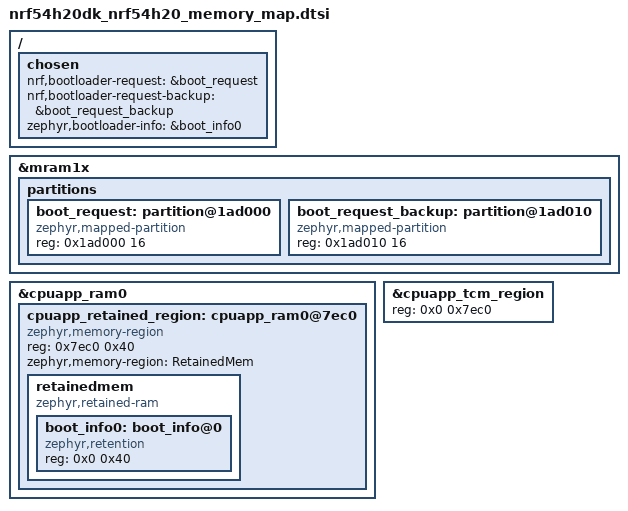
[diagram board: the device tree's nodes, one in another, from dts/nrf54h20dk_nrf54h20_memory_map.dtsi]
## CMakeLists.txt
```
#
# Copyright (c) 2025 Nordic Semiconductor ASA
#
# SPDX-License-Identifier: LicenseRef-Nordic-5-Clause
#

cmake_minimum_required(VERSION 3.20.0)

find_package(Zephyr REQUIRED HINTS $ENV{ZEPHYR_BASE})
project(ab_split)

target_sources(app PRIVATE
  src/main.c
  src/ab_utils.c
)

target_include_directories(app PRIVATE
  ${ZEPHYR_MCUBOOT_MODULE_DIR}/boot/bootutil/include
  ${ZEPHYR_MCUBOOT_MODULE_DIR}/boot/zephyr/include
  ${ZEPHYR_BASE}/samples/subsys/mgmt/mcumgr/smp_svr/src
)

target_sources_ifdef(CONFIG_MCUMGR_TRANSPORT_BT app PRIVATE
  ${ZEPHYR_BASE}/samples/subsys/mgmt/mcumgr/smp_svr/src/bluetooth.c
)
```

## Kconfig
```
#
# Copyright (c) 2025 Nordic Semiconductor ASA
#
# SPDX-License-Identifier: LicenseRef-Nordic-5-Clause
#

config N_BLINKS
	int "Number of fast blinks"
	default 1

config EMULATE_APP_HEALTH_CHECK_FAILURE
	bool "Blocks confirmation of being healthy after the update"

source "Kconfig.zephyr"
```

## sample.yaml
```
sample:
  description: AB update sample with separated slots
  name: ab_split
common:
  sysbuild: true
  build_only: true
  tags:
    - dfu_ab
    - ci_samples_dfu

tests:
  sample.dfu.ab_split:
    extra_configs:
      - CONFIG_MCUMGR_GRP_IMG_ALLOW_CONFIRM_NON_ACTIVE_IMAGE_ANY=y
    platform_allow:
      - nrf54h20dk/nrf54h20/cpuapp
    integration_platforms:
      - nrf54h20dk/nrf54h20/cpuapp

  sample.dfu.ab_split.ironside_se_conf:
    extra_configs:
      - CONFIG_MCUMGR_GRP_IMG_ALLOW_CONFIRM_NON_ACTIVE_IMAGE_ANY=y
    platform_allow:
      - nrf54h20dk/nrf54h20/cpuapp
    integration_platforms:
      - nrf54h20dk/nrf54h20/cpuapp
    extra_args:
      - FILE_SUFFIX=ironside_se_conf
```

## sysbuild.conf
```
# Enable MCUboot bootloader support
SB_CONFIG_BOOTLOADER_MCUBOOT=y

# Enable radiocore
SB_CONFIG_NETCORE_IPC_RADIO=y
SB_CONFIG_NETCORE_IPC_RADIO_BT_HCI_IPC=y

# Enable direct XIP with revert support
SB_CONFIG_MCUBOOT_MODE_DIRECT_XIP_WITH_REVERT=y

# Disable merging of slots
SB_CONFIG_MCUBOOT_SIGN_MERGED_BINARY=n

# Enable manifest-based updates
SB_CONFIG_MCUBOOT_MANIFEST_UPDATES=y

# Enable HW-based rollback protection
SB_CONFIG_MCUBOOT_HARDWARE_DOWNGRADE_PREVENTION=y
```

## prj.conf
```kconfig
# Enable MCUmgr and dependencies.
CONFIG_NET_BUF=y
CONFIG_ZCBOR=y
CONFIG_CRC=y
CONFIG_MCUMGR=y
CONFIG_STREAM_FLASH=y
CONFIG_FLASH_MAP=y

# Some command handlers require a large stack.
CONFIG_SYSTEM_WORKQUEUE_STACK_SIZE=2304
CONFIG_MAIN_STACK_SIZE=2176

# Ensure an MCUboot-compatible binary is generated.
CONFIG_BOOTLOADER_MCUBOOT=y

# Enable flash operations.
CONFIG_FLASH=y

# Required by the `taskstat` command.
CONFIG_THREAD_MONITOR=y

# Support for taskstat command
CONFIG_MCUMGR_GRP_OS_TASKSTAT=y

# Enable statistics and statistic names.
CONFIG_STATS=y
CONFIG_STATS_NAMES=y

# Enable most core commands.
CONFIG_FLASH=y
CONFIG_IMG_MANAGER=y
CONFIG_MCUMGR_GRP_IMG=y
CONFIG_MCUMGR_GRP_IMG_NRF=y
CONFIG_MCUMGR_GRP_OS=y
CONFIG_MCUMGR_GRP_STAT=y

# Enable logging
CONFIG_LOG=y
CONFIG_MCUBOOT_UTIL_LOG_LEVEL_WRN=y

# Disable debug logging
CONFIG_LOG_MAX_LEVEL=3

# Enable boot requests.
CONFIG_NRF_MCUBOOT_BOOT_REQUEST=y

# Enable DK LED/button library
CONFIG_DK_LIBRARY=y

# Configure bluetooth

CONFIG_BT=y
CONFIG_BT_PERIPHERAL=y

# Allow for large Bluetooth data packets.
CONFIG_BT_L2CAP_TX_MTU=498
CONFIG_BT_BUF_ACL_RX_SIZE=502
CONFIG_BT_BUF_ACL_TX_SIZE=502

# Enable the Bluetooth mcumgr transport (unauthenticated).
CONFIG_MCUMGR_TRANSPORT_BT=y
CONFIG_MCUMGR_TRANSPORT_BT_CONN_PARAM_CONTROL=y

# Enable the Shell mcumgr transport.
CONFIG_BASE64=y
CONFIG_CRC=y
CONFIG_SHELL=y
CONFIG_SHELL_BACKEND_SERIAL=y
CONFIG_MCUMGR_TRANSPORT_SHELL=y

# Enable the mcumgr Packet Reassembly feature over Bluetooth and its configuration dependencies.
# MCUmgr buffer size is optimized to fit one SMP packet divided into five Bluetooth Write Commands,
# transmitted with the maximum possible MTU value: 498 bytes.
CONFIG_MCUMGR_TRANSPORT_BT_REASSEMBLY=y
CONFIG_MCUMGR_TRANSPORT_NETBUF_SIZE=2475
CONFIG_MCUMGR_GRP_OS_MCUMGR_PARAMS=y
CONFIG_MCUMGR_TRANSPORT_WORKQUEUE_STACK_SIZE=4608

# Enable the LittleFS file system.
CONFIG_FILE_SYSTEM=y
CONFIG_FILE_SYSTEM_LITTLEFS=y

# Enable file system commands
CONFIG_MCUMGR_GRP_FS=y

# Enable the storage erase command.
CONFIG_MCUMGR_GRP_ZBASIC=y
CONFIG_MCUMGR_GRP_ZBASIC_STORAGE_ERASE=y

# Disable Bluetooth ping support
CONFIG_BT_CTLR_LE_PING=n

# Disable shell commands that are not needed
CONFIG_CLOCK_CONTROL_NRF_SHELL=n
CONFIG_DEVICE_SHELL=n
CONFIG_DEVMEM_SHELL=n
CONFIG_FLASH_SHELL=n

# Read bootloader version and security counters values from the retained RAM
CONFIG_RETAINED_MEM=y
CONFIG_RETENTION=y
CONFIG_RETENTION_BOOTLOADER_INFO=y
CONFIG_RETENTION_BOOTLOADER_INFO_TYPE_MCUBOOT=y

# Enable S2RAM
CONFIG_PM=y
CONFIG_PM_DEVICE=y
CONFIG_PM_DEVICE_RUNTIME=y
CONFIG_POWEROFF=y
```

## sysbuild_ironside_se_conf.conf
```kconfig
SB_CONFIG_NCS_MCUBOOT_LOAD_PERIPHCONF=y
SB_CONFIG_NCS_MCUBOOT_MPCCONF_STATIC_WRITE_PROTECTION=y

# Enable MCUboot bootloader support
SB_CONFIG_BOOTLOADER_MCUBOOT=y

# Enable radiocore
SB_CONFIG_NETCORE_IPC_RADIO=y
SB_CONFIG_NETCORE_IPC_RADIO_BT_HCI_IPC=y

# Enable direct XIP with revert support
SB_CONFIG_MCUBOOT_MODE_DIRECT_XIP_WITH_REVERT=y

# Disable merging of slots
SB_CONFIG_MCUBOOT_SIGN_MERGED_BINARY=n

# Enable manifest-based updates
SB_CONFIG_MCUBOOT_MANIFEST_UPDATES=y

# Enable HW-based rollback protection
SB_CONFIG_MCUBOOT_HARDWARE_DOWNGRADE_PREVENTION=y
```

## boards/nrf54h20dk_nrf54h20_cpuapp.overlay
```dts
/*
 * Copyright (c) 2025 Nordic Semiconductor ASA
 *
 * SPDX-License-Identifier: LicenseRef-Nordic-5-Clause
 */

#include "../dts/nrf54h20dk_nrf54h20_memory_map.dtsi"

/ {
	chosen {
		zephyr,boot-mode = &boot_request;
	};
};
```

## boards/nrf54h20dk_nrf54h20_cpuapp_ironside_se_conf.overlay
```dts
/*
 * Copyright (c) 2026 Nordic Semiconductor ASA
 *
 * SPDX-License-Identifier: LicenseRef-Nordic-5-Clause
 */

#include "../dts/nrf54h20dk_nrf54h20_memory_map.dtsi"
#include "../dts/nrf54h20dk_nrf54h20_memory_map_ironside_se_conf.dtsi"

/ {
	chosen {
		zephyr,boot-mode = &boot_request;
	};
};
```

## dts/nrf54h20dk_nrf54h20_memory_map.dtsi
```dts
/*
 * Copyright (c) 2025 Nordic Semiconductor ASA
 *
 * SPDX-License-Identifier: LicenseRef-Nordic-5-Clause
 */

/ {
	chosen {
		nrf,bootloader-request = &boot_request;
		nrf,bootloader-request-backup = &boot_request_backup;
		zephyr,bootloader-info = &boot_info0;
	};
};

&mram1x {
	partitions {
		boot_request: partition@1ad000 {
			compatible = "zephyr,mapped-partition";
			reg = <0x1ad000 16>;
		};

		boot_request_backup: partition@1ad010 {
			compatible = "zephyr,mapped-partition";
			reg = <0x1ad010 16>;
		};
	};
};

&cpuapp_ram0 {
	cpuapp_retained_region: cpuapp_ram0@7ec0 {
		compatible = "zephyr,memory-region", "mmio-sram";
		reg = <0x7ec0 0x40>;
		zephyr,memory-region = "RetainedMem";
		status = "okay";

		retainedmem {
			compatible = "zephyr,retained-ram";
			status = "okay";
			#address-cells = <1>;
			#size-cells = <1>;

			boot_info0: boot_info@0 {
				compatible = "zephyr,retention";
				status = "okay";
				reg = <0x0 0x40>;
			};
		};
	};
};

&cpuapp_tcm_region {
	reg = <0x0 0x7ec0>;
};
```

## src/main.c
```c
/*
 * Copyright (c) 2012-2014 Wind River Systems, Inc.
 * Copyright (c) 2020 Prevas A/S
 * Copyright (c) 2025 Nordic Semiconductor ASA
 *
 * SPDX-License-Identifier: LicenseRef-Nordic-5-Clause
 */

#include <zephyr/kernel.h>
#include <common.h>
#include "ab_utils.h"

#ifdef CONFIG_RETENTION_BOOTLOADER_INFO
#include <zephyr/retention/blinfo.h>
#include <bootutil/image.h>
#endif

#define LOG_LEVEL LOG_LEVEL_DBG
#include <zephyr/logging/log.h>
LOG_MODULE_REGISTER(ab_sample);

#ifdef CONFIG_RETENTION_BOOTLOADER_INFO
static void blinfo_bootloader_version(void)
{
	struct image_version version = {0x00};

	int ret = blinfo_lookup(BLINFO_BOOTLOADER_VERSION, (char *)&version,
				sizeof(struct image_version));

	if (ret < 0) {
		LOG_INF("blinfo_lookup error: %d", ret);
	} else {
		LOG_INF("Bootloader version: %d.%d.%d+%d", version.iv_major,
			version.iv_minor, version.iv_revision, version.iv_build_num);
	}
}

#ifdef CONFIG_MCUBOOT_HARDWARE_DOWNGRADE_PREVENTION
static void blinfo_security_counter(void)
{
	uint32_t counter = 0;

	int ret = blinfo_lookup(BLINFO_SECURITY_COUNTER_IMAGE_0, (char *)&counter,
				sizeof(counter));

	if (ret < 0) {
		LOG_INF("blinfo_lookup error: %d", ret);
	} else {
		LOG_INF("Security counter: %d", counter);
	}
}
#endif /* CONFIG_MCUBOOT_HARDWARE_DOWNGRADE_PREVENTION */
#endif /* CONFIG_RETENTION_BOOTLOADER_INFO */

int main(void)
{
#ifdef CONFIG_RETENTION_BOOTLOADER_INFO
	blinfo_bootloader_version();
#ifdef CONFIG_MCUBOOT_HARDWARE_DOWNGRADE_PREVENTION
	blinfo_security_counter();
#endif /* CONFIG_MCUBOOT_HARDWARE_DOWNGRADE_PREVENTION */
#endif

#ifdef CONFIG_MCUMGR_TRANSPORT_BT
	start_smp_bluetooth_adverts();
#endif

	/* Give BLE a moment to start up */
	k_sleep(K_MSEC(1000));

	ab_actions_perform();

	/* using __TIME__ ensure that a new binary will be built on every
	 * compile which is convenient when testing firmware upgrade.
	 */
	LOG_INF("build time: " __DATE__ " " __TIME__);

	/* The system work queue handles all incoming mcumgr requests.  Let the
	 * main thread idle while the mcumgr server runs.
	 */
	while (1) {
		k_sleep(K_MSEC(1000));
	}

	return 0;
}
```

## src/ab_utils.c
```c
/*
 * Copyright (c) 2025 Nordic Semiconductor ASA
 *
 * SPDX-License-Identifier: LicenseRef-Nordic-5-Clause
 */

#include <zephyr/kernel.h>
#include <zephyr/logging/log.h>
#include <zephyr/bluetooth/bluetooth.h>
#include <bootutil/bootutil_public.h>
#include <bootutil/boot_request.h>

#include <dk_buttons_and_leds.h>

LOG_MODULE_DECLARE(ab_sample);

#define CODE_PARTITION DT_CHOSEN(zephyr_code_partition)
#define CODE_PARTITION_OFFSET PARTITION_NODE_OFFSET(CODE_PARTITION)

#define SLOT_A_PARTITION cpuapp_slot0_partition
#define SLOT_B_PARTITION cpuapp_slot1_partition

#define SLOT_A_OFFSET PARTITION_OFFSET(SLOT_A_PARTITION)
#define SLOT_B_OFFSET PARTITION_OFFSET(SLOT_B_PARTITION)
#define SLOT_A_SIZE   PARTITION_SIZE(SLOT_A_PARTITION)
#define SLOT_B_SIZE   PARTITION_SIZE(SLOT_B_PARTITION)

#define SLOT_A_FLASH_AREA_ID PARTITION_ID(SLOT_A_PARTITION)
#define SLOT_B_FLASH_AREA_ID PARTITION_ID(SLOT_B_PARTITION)

#define IS_SLOT_A                                                                                  \
	(CODE_PARTITION_OFFSET >= SLOT_A_OFFSET &&                                                 \
	 CODE_PARTITION_OFFSET < SLOT_A_OFFSET + SLOT_A_SIZE)
#define IS_SLOT_B                                                                                  \
	(CODE_PARTITION_OFFSET >= SLOT_B_OFFSET &&                                                 \
	 CODE_PARTITION_OFFSET < SLOT_B_OFFSET + SLOT_B_SIZE)

#define STATUS_LEDS_THREAD_STACK_SIZE 512
#define STATUS_LEDS_THREAD_PRIORITY (CONFIG_NUM_PREEMPT_PRIORITIES - 1)
K_THREAD_STACK_DEFINE(status_leds_thread_stack_area, STATUS_LEDS_THREAD_STACK_SIZE);

/** @brief Radio firmware self test
 *
 * @details
 * End-device specific self test should be implemented here.
 */
static bool radio_domain_healthy(void)
{
	return bt_is_ready();
}

/** @brief Application firmware self test
 *
 * @details
 * End-device specific self test should be implemented here. Enabling
 * CONFIG_EMULATE_APP_HEALTH_CHECK_FAILURE allows to emulate a faulty
 * firmware, unable to confirm its health, and ultimately to test
 * a rollback to previous firmware after the update.
 */
static bool app_domain_healthy(void)
{
	if (IS_ENABLED(CONFIG_EMULATE_APP_HEALTH_CHECK_FAILURE)) {
		return false;
	}

	return true;
}

static enum boot_slot active_boot_slot_get(void)
{
	enum boot_slot active_slot = BOOT_SLOT_NONE;

	if (IS_SLOT_A) {
		active_slot = BOOT_SLOT_PRIMARY;
	} else if (IS_SLOT_B) {
		active_slot = BOOT_SLOT_SECONDARY;
	} else {
		LOG_ERR("Cannot determine current slot");
	}

	return active_slot;
}

static bool slot_confirmed(enum boot_slot slot)
{
	struct boot_swap_state state;
	const struct flash_area *fa;
	int area_id = -1;
	char *img_set = NULL;
	bool confirmed = false;
	int ret;

	if (slot == BOOT_SLOT_PRIMARY) {
		img_set = "A";
		area_id = SLOT_A_FLASH_AREA_ID;
	} else if (slot == BOOT_SLOT_SECONDARY) {
		img_set = "B";
		area_id = SLOT_B_FLASH_AREA_ID;
	} else {
		LOG_ERR("Cannot determine slot to check for confirmation");
		return false;
	}

	if (flash_area_open(area_id, &fa) != 0) {
		LOG_ERR("Cannot open flash area for slot %s", img_set);
		return false;
	}

	ret = boot_read_swap_state(fa, &state);
	if (ret != 0) {
		LOG_ERR("Cannot read swap state for slot %s", img_set);
	} else if (state.image_ok == BOOT_FLAG_SET) {
		confirmed = true;
	} else {
		confirmed = false;
	}

	flash_area_close(fa);

	return confirmed;
}

static void device_healthcheck(void)
{
	int err;
	char *img_set = NULL;
	enum boot_slot active_slot = active_boot_slot_get();

	/* Confirming only in non-degraded boot states */
	if (active_slot == BOOT_SLOT_PRIMARY) {
		img_set = "A";
	} else if (active_slot == BOOT_SLOT_SECONDARY) {
		img_set = "B";
	} else {
		LOG_ERR("Cannot determine active slot for health check");
		return;
	}

	if (slot_confirmed(active_slot)) {
		LOG_INF("Slot %s already confirmed, no action needed", img_set);
		return;
	}

	LOG_INF("Testing image set %s...", img_set);

	bool healthy = true;

	if (!radio_domain_healthy()) {
		LOG_ERR("Radio domain is NOT healthy");
		healthy = false;
	}

	if (!app_domain_healthy()) {
		LOG_ERR("App domain is NOT healthy");
		healthy = false;
	}

	if (!healthy) {
		LOG_ERR("Reboot the device to try to boot from previous firmware");
		return;
	}

	LOG_INF("Confirming...");

	err = boot_request_confirm_slot(CONFIG_NCS_MCUBOOT_MANIFEST_IMAGE_INDEX, active_slot);
	if (err == 0) {
		LOG_INF("Confirmed\n");
	} else {
		LOG_ERR("Failed to confirm, err: %d", err);
	}
}

static void select_slot_for_single_boot(enum boot_slot slot)
{
	int err = 0;
	char active_slot = (active_boot_slot_get() == BOOT_SLOT_PRIMARY) ? 'A' : 'B';

#ifdef CONFIG_NRF_MCUBOOT_BOOT_REQUEST_PREFERENCE_KEEP
	if (slot == BOOT_SLOT_PRIMARY) {
		LOG_INF("Switching slots (%c -> A)", active_slot);
	} else if (slot == BOOT_SLOT_SECONDARY) {
		LOG_INF("Switching slots (%c -> B)", active_slot);
	} else {
		LOG_ERR("Cannot determine active slot, cannot toggle");
		return;
	}
#else
	if (slot == BOOT_SLOT_PRIMARY) {
		LOG_INF("Temporarily switching slots (%c -> A)", active_slot);
	} else if (slot == BOOT_SLOT_SECONDARY) {
		LOG_INF("Temporarily switching slots (%c -> B)", active_slot);
	} else {
		LOG_ERR("Cannot determine active slot, cannot toggle");
		return;
	}
#endif

	err = boot_request_set_preferred_slot(CONFIG_NCS_MCUBOOT_MANIFEST_IMAGE_INDEX, slot);
	if (err == 0) {
		LOG_INF("Slot toggled, restart the device to enforce");
	} else {
		LOG_ERR("Failed to toggle slots, err: %d", err);
	}
}

static void boot_state_report(void)
{
	enum boot_slot active_slot = active_boot_slot_get();

	if (active_slot == BOOT_SLOT_PRIMARY) {
		LOG_INF("Booted from slot A");
	} else if (active_slot == BOOT_SLOT_SECONDARY) {
		LOG_INF("Booted from slot B");
	} else {
		LOG_INF("Cannot determine active slot");
	}
}

static void button_handler(uint32_t button_state, uint32_t has_changed)
{
	if ((has_changed & DK_BTN1_MSK) && (button_state & DK_BTN1_MSK)) {
		select_slot_for_single_boot(BOOT_SLOT_PRIMARY);
	} else if ((has_changed & DK_BTN2_MSK) && (button_state & DK_BTN2_MSK)) {
		select_slot_for_single_boot(BOOT_SLOT_SECONDARY);
	}
}

struct k_thread status_leds_thread_data;

static void status_leds_thread_entry_point(void *p1, void *p2, void *p3)
{
	int blinking_led = DK_LED1;
	enum boot_slot active_slot = active_boot_slot_get();

	if (active_slot == BOOT_SLOT_PRIMARY) {
		blinking_led = DK_LED1;
	} else if (active_slot == BOOT_SLOT_SECONDARY) {
		blinking_led = DK_LED2;
	} else {
		return;
	}

	while (1) {
		for (int i = 0; i < CONFIG_N_BLINKS; i++) {
			dk_set_led_off(blinking_led);
			k_msleep(250);
			dk_set_led_on(blinking_led);
			k_msleep(250);
		}

		k_msleep(5000);
	}
}

void ab_actions_perform(void)
{
	int ret;

	boot_state_report();

	ret = dk_leds_init();
	if (ret) {
		LOG_ERR("Cannot init LEDs (err: %d)", ret);
	}

	ret = dk_buttons_init(button_handler);
	if (ret) {
		LOG_ERR("Cannot init buttons (err: %d)", ret);
	}

	k_thread_create(&status_leds_thread_data, status_leds_thread_stack_area,
			K_THREAD_STACK_SIZEOF(status_leds_thread_stack_area),
			status_leds_thread_entry_point,
			NULL, NULL, NULL,
			STATUS_LEDS_THREAD_PRIORITY, 0, K_NO_WAIT);

	device_healthcheck();
}
```

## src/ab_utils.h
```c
/*
 * Copyright (c) 2025 Nordic Semiconductor ASA
 *
 * SPDX-License-Identifier: LicenseRef-Nordic-5-Clause
 */

void ab_actions_perform(void);
```
